AUTOSAR XML (schema 4-0-2)
package /AUTOSAR_ComM/SwcImplementations
  swc implementation ComM_Imp: programming-language=C, behavior=ComM_Int
    code-descriptors:
      code ComM_Imp_Code: artifact-descriptors=autosar-engineering-object={short-label=Code, category=SWSRC}
package /AUTOSAR_ComM/ImplementationDataTypes
  impl type ComM_UserHandleArrayType: category=STRUCTURE
    element numberOfRequesters: implementation-data-type=uint8
    element handleArray: category=ARRAY, array-size-semantics=FIXED-SIZE
      element handleArrayElement: array-size=1, implementation-data-type=ComM_UserHandleType
package /AUTOSAR_ComM/SwComponentTypes
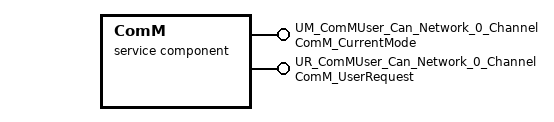
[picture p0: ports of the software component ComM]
  service sw component type ComM
    provide port UM_ComMUser_Can_Network_0_Channel: mode-switch-sender-com-spec{mode-group=currentMode, queue-length=1}, provided-interface=ComM_CurrentMode
    provide port UR_ComMUser_Can_Network_0_Channel: server-com-spec{operation=RequestComMode, queue-length=5}, provided-interface=ComM_UserRequest
    behavior ComM_Int: data-type-mapping=ComMModeMapping
      4 x operation invoked event:
        OIE_UR_ComMUser_Can_Network_0_Channel_RequestComMode: start-on-event=RequestComMode, operation=UR_ComMUser_Can_Network_0_Channel.RequestComMode
        OIE_UR_ComMUser_Can_Network_0_Channel_GetRequestedComMode: start-on-event=GetRequestedComMode, operation=UR_ComMUser_Can_Network_0_Channel.GetRequestedComMode
        OIE_UR_ComMUser_Can_Network_0_Channel_GetCurrentComMode: start-on-event=GetCurrentComMode, operation=UR_ComMUser_Can_Network_0_Channel.GetCurrentComMode
        OIE_UR_ComMUser_Can_Network_0_Channel_GetMaxComMode: start-on-event=GetMaxComMode, operation=UR_ComMUser_Can_Network_0_Channel.GetMaxComMode
      port-api-options:
        {enable-take-address=false, indirect-api=true, port-defined-argument-value{value=UM_ComMUser_Can_Network_0_Channel:0, value-type=ComM_UserHandleType}, port=UM_ComMUser_Can_Network_0_Channel}
        {enable-take-address=false, indirect-api=false, port-defined-argument-value{value=UR_ComMUser_Can_Network_0_Channel:0, value-type=ComM_UserHandleType}, port=UR_ComMUser_Can_Network_0_Channel}
      4 x runnable, all with can-be-invoked-concurrently=true:
        RequestComMode: symbol=ComM_RequestComMode
        GetMaxComMode: symbol=ComM_GetMaxComMode
        GetRequestedComMode: symbol=ComM_GetRequestedComMode
        GetCurrentComMode: symbol=ComM_GetCurrentComMode
          mode switch point MSP_ComM_User_ComMUser_Can_Network_0_Channel: mode-group=UM_ComMUser_Can_Network_0_Channel.currentMode
package /AUTOSAR_ComM/PortInterfaces
  sender receiver interface ComM_CurrentChannelRequest: is-service=true
    data fullComRequestors: type=ComM_UserHandleArrayType
